# AVR32DD28 device description
Architecture: AVR8X; Family: AVR
Registers are 8-bit, read-write, reset 0x0 unless marked. A register's access mark holds for its fields unless they carry their own. Offsets are from the block's base; [hi:lo] are bit positions; {n}, {i} and the like mark numbered series; 'fields as' and 'values as' point back to an identical list.

## NVMCTRL — Non-volatile Memory Controller
Instances: NVMCTRL 0x1000
0x00 CTRLA — Control A
  [6:0] CMD — Command
    0=NONE (No Command); 1=NOOP (No Operation); 2=FLWR (Flash Write); 8=FLPER (Flash Page Erase); 9=FLMPER2 (Flash Multi-Page Erase 2 pages); 10=FLMPER4 (Flash Multi-Page Erase 4 pages); 11=FLMPER8 (Flash Multi-Page Erase 8 pages); 12=FLMPER16 (Flash Multi-Page Erase 16 pages); 13=FLMPER32 (Flash Multi-Page Erase 32 pages); 18=EEWR (EEPROM Write); 19=EEERWR (EEPROM Erase and Write); 24=EEBER (EEPROM Byte Erase); 25=EEMBER2 (EEPROM Multi-Byte Erase 2 bytes); 26=EEMBER4 (EEPROM Multi-Byte Erase 4 bytes); 27=EEMBER8 (EEPROM Multi-Byte Erase 8 bytes); 28=EEMBER16 (EEPROM Multi-Byte Erase 16 bytes); 29=EEMBER32 (EEPROM Multi-Byte Erase 32 bytes); 32=CHER (Chip Erase Command); 48=EECHER (EEPROM Erase Command)
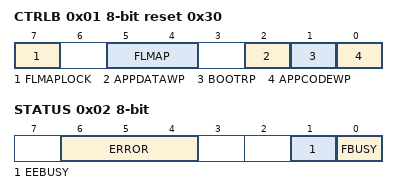
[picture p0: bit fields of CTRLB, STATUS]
0x01 CTRLB reset 0x30 — Control B
  [7] FLMAPLOCK — Flash Mapping Lock
  [5:4] FLMAP — Flash Mapping in Data space
    {v}=SECTION{v} (Flash section {v}) (v=0..3)
  [2] APPDATAWP — Application Data Write Protect
  [1] BOOTRP — Boot Read Protect
  [0] APPCODEWP — Application Code Write Protect
0x02 STATUS ro
  [6:4] ERROR — Write error
    0=NOERROR; 1=ILLEGALCMD (Write command not selected); 2=ILLEGALSADDR (Write to section not allowed); 3=DOUBLESELECT (Selecting new write command while write command already seleted); 4=ONGOINGPROG (Starting a new programming operation before previous is completed)
  [1] EEBUSY — EEPROM busy
  [0] FBUSY — Flash busy
0x03 INTCTRL — Interrupt Control
  [0] EEREADY — EEPROM Ready
0x04 INTFLAGS — Interrupt Flags
  [0] EEREADY — EEPROM Ready
0x06 DATA 16-bit reset not defined
0x08 ADDR 32-bit reset not defined — Address

## PORT — I/O Ports
Instances: PORTA 0x0400, PORTC 0x0440, PORTD 0x0460, PORTF 0x04A0
0x00 DIR reset not defined — Data Direction
0x01 DIRSET reset not defined — Data Direction Set
0x02 DIRCLR reset not defined — Data Direction Clear
0x03 DIRTGL reset not defined — Data Direction Toggle
0x04 OUT reset not defined — Output Value
0x05 OUTSET reset not defined — Output Value Set
0x06 OUTCLR reset not defined — Output Value Clear
0x07 OUTTGL reset not defined — Output Value Toggle
0x08 IN reset not defined — Input Value
0x09 INTFLAGS — Interrupt Flags
  [7:0] INT — Pin Interrupt Flag
0x0A PORTCTRL — Port Control
  [0] SRL — Slew Rate Limit Enable
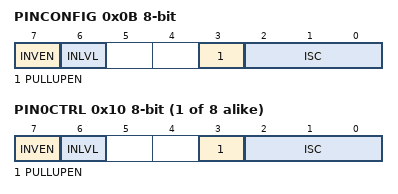
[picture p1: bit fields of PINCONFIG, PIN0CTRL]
0x0B PINCONFIG — Pin Control Config
  [7] INVEN — Inverted I/O Enable
  [6] INLVL — Input level select
  [3] PULLUPEN — Pullup enable
  [2:0] ISC — Input/Sense Configuration
    0=INTDISABLE (Interrupt disabled but input buffer enabled); 1=BOTHEDGES (Sense Both Edges); 2=RISING (Sense Rising Edge); 3=FALLING (Sense Falling Edge); 4=INPUT_DISABLE (Digital Input Buffer disabled); 5=LEVEL (Sense low Level)
0x0C PINCTRLUPD — Pin Control Update
  [7:0] PINCTRLUPD — Pin control update mask
0x0D PINCTRLSET — Pin Control Set
  [7:0] PINCTRLSET — Pin control set mask
0x0E PINCTRLCLR — Pin Control Clear
  [7:0] PINCTRLCLR — Pin control clear mask
{0x10+i} PIN{i}CTRL (i=0..7) — Pin {i} Control
  fields as PINCONFIG

## PORTMUX — Port Multiplexer
Instances: PORTMUX 0x05E0
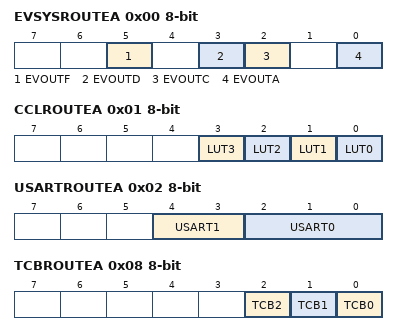
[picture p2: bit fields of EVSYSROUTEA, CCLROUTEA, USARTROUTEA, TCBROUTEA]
0x00 EVSYSROUTEA
  [5] EVOUTF — Event Output F
    0=DEFAULT (EVOUT on PF2)
  [3] EVOUTD — Event Output D
    0=DEFAULT (EVOUT on PD2); 1=ALT1 (EVOUT on PD7)
  [2] EVOUTC — Event Output C
    0=DEFAULT (EVOUT on PC2); 1=ALT1 (EVOUT on PC7)
  [0] EVOUTA — Event Output A
    0=DEFAULT (EVOUT on PA2); 1=ALT1 (EVOUT on PA7)
0x01 CCLROUTEA
  [3] LUT3 — CCL Look-Up Table 3 Signals
    0=DEFAULT (Out: PF3 In: PF0, PF1, PF2)
  [2] LUT2 — CCL Look-Up Table 2 Signals
    0=DEFAULT (Out: PD3 In: PD0, PD1, PD2); 1=ALT1 (Out: PD6 In: PD0, PD1, PD2)
  [1] LUT1 — CCL Look-Up Table 1 Signals
    0=DEFAULT (Out: PC3 In: PC0, PC1, PC2); 1=ALT1 (Out: PC6 In: PC0, PC1, PC2)
  [0] LUT0 — CCL Look-Up Table 0 Signals
    0=DEFAULT (Out: PA3 In: PA0, PA1, PA2); 1=ALT1 (Out: PA6 In: PA0, PA1, PA2)
0x02 USARTROUTEA
  [4:3] USART1 — USART1 Signals
    0=DEFAULT (PC0, PC1, PC2, PC3); 2=ALT2 (PD6, PD7); 3=NONE (Not connected to any pins)
  [2:0] USART0 — USART0 Signals
    0=DEFAULT (PA0, PA1, PA2, PA3); 1=ALT1 (PA4, PA5, PA6, PA7); 2=ALT2 (PA2, PA3); 3=ALT3 (PD4, PD5, PD6, PD7); 4=ALT4 (PC1, PC2, PC3); 5=NONE (Not connected to any pins)
0x05 SPIROUTEA
  [2:0] SPI0 — SPI0 Signals
    0=DEFAULT (PA4, PA5, PA6, PA7); 1=ALT1 (PE0, PE1, PE2, PE3); 2=ALT2 (PG4, PG5, PG6, PG7); 3=ALT3 (PA0, PA1, PC0, PC1); 4=ALT4 (PD4, PD5, PD6, PD7); 5=ALT5 (PC0, PC1, PC2, PC3); 6=ALT6 (PC1, PC2, PC3, PF7); 7=NONE (NA, NA, NA, Set to 1)
0x06 TWIROUTEA
  [1:0] TWI0 — TWI0 Signals
    0=DEFAULT (PA2, PA3, PC2, PC3); 1=ALT1 (PA2, PA3, PC6, PC7); 2=ALT2 (PC2, PC3, PC6, PC7); 3=ALT3 (PA0, PA1, PC2, PC3)
0x07 TCAROUTEA
  [2:0] TCA0 — TCA0 Signals
    0=PORTA (PA0, PA1, PA2, PA3, PA4, PA5); 1=PORTB (PB0, PB1, PB2, PB3, PB4, PB5); 2=PORTC (PC0, PC1, PC2, PC3, PC4, PC5); 3=PORTD (PD0, PD1, PD2, PD3, PD4, PD5); 4=PORTE (PE0, PE1, PE2, PE3, PE4, PE5); 5=PORTF (PF0, PF1, PF2, PF3, PF4, PF5); 6=PORTG (PG0, PG1, PG2, PG3, PG4, PG5)
0x08 TCBROUTEA
  [2] TCB2 — TCB2 Output
    0=DEFAULT (WO on PC0); 1=ALT1 (WO on PB4)
  [1] TCB1 — TCB1 Output
    0=DEFAULT (WO on PA3); 1=ALT1 (WO on PF5)
  [0] TCB0 — TCB0 Output
    0=DEFAULT (WO on PA2); 1=ALT1 (WO on PF4)
0x09 TCDROUTEA
  [2:0] TCD0 — TCD0 Signals
    0=DEFAULT (PA4, PA5, PA6, PA7); 1=ALT1 (PB4, PB5, PB6, PB7); 2=ALT2 (PF0, PF1, PF2, PF3); 3=ALT3 (PG4, PG5, PG6, PG7); 4=ALT4 (PA4, PA5, PD4, PD5)
